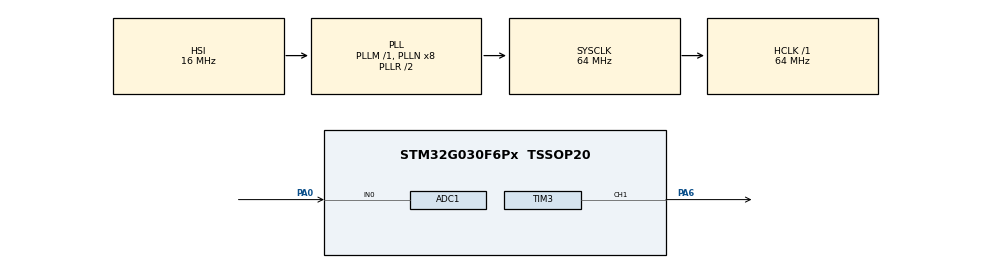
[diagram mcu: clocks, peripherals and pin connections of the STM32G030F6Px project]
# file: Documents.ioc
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ADC1.Channel-0\#ChannelRegularConversion=ADC_CHANNEL_0
ADC1.NbrOfConversionFlag=1
ADC1.Rank-0\#ChannelRegularConversion=1
ADC1.SamplingTime-0\#ChannelRegularConversion=ADC_SAMPLINGTIME_COMMON_1
ADC1.SamplingTimeCommon1=ADC_SAMPLETIME_160CYCLES_5
ADC1.SelectedChannel=ADC_CHANNEL_0
ADC1.master=1
Dma.Request0=TIM3_CH1
Dma.TIM3_CH1.0.Direction=DMA_MEMORY_TO_PERIPH
Dma.TIM3_CH1.0.EventEnable=DISABLE
Dma.TIM3_CH1.0.Instance=DMA1_Channel1
Dma.TIM3_CH1.0.MemDataAlignment=DMA_MDATAALIGN_HALFWORD
Dma.TIM3_CH1.0.MemInc=DMA_MINC_ENABLE
Dma.TIM3_CH1.0.Mode=DMA_NORMAL
Dma.TIM3_CH1.0.PeriphDataAlignment=DMA_PDATAALIGN_HALFWORD
Dma.TIM3_CH1.0.PeriphInc=DMA_PINC_DISABLE
Dma.TIM3_CH1.0.Polarity=HAL_DMAMUX_REQ_GEN_RISING
Dma.TIM3_CH1.0.Priority=DMA_PRIORITY_LOW
Dma.TIM3_CH1.0.RequestNumber=1
Dma.TIM3_CH1.0.SignalID=NONE
Dma.TIM3_CH1.0.SyncEnable=DISABLE
Dma.TIM3_CH1.0.SyncPolarity=HAL_DMAMUX_SYNC_NO_EVENT
Dma.TIM3_CH1.0.SyncRequestNumber=1
Dma.TIM3_CH1.0.SyncSignalID=NONE
Mcu.Family=STM32G0
Mcu.Name=STM32G030F6Px
Mcu.Package=TSSOP20
NVIC.DMA1_Channel1_IRQn=true\:0\:0\:false\:false\:true\:false\:true\:true
PA0.Mode=IN0
PA0.Signal=ADC1_IN0
PA13.Mode=Serial_Wire
PA13.Signal=SYS_SWDIO
PA14-BOOT0.Mode=Serial_Wire
PA14-BOOT0.Signal=SYS_SWCLK
PA14-BOOT0__PA15.StandardMode=true
PA6.Signal=S_TIM3_CH1
PB0__PB1__PB2__PA8.StandardMode=true
PB3__PB4__PB5__PB6.StandardMode=true
PB7__PB8.StandardMode=true
PC14-OSC32_IN\ (PC14)__PB9.StandardMode=true
ProjectManager.HeapSize=0x200
ProjectManager.StackSize=0x400
ProjectManager.TargetToolchain=Makefile
RCC.ADCFreq_Value=64000000
RCC.AHBFreq_Value=64000000
RCC.CortexFreq_Value=64000000
RCC.EXTERNAL_CLOCK_VALUE=12288000
RCC.HCLKFreq_Value=64000000
RCC.HSE_VALUE=8000000
RCC.HSI_VALUE=16000000
RCC.LSE_VALUE=32768
RCC.SYSCLKFreq_VALUE=64000000
RCC.SYSCLKSource=RCC_SYSCLKSOURCE_PLLCLK
RCC.VCOOutputFreq_Value=128000000
SH.S_TIM3_CH1.0=TIM3_CH1,PWM Generation1 CH1
TIM3.AutoReloadPreload=TIM_AUTORELOAD_PRELOAD_ENABLE
TIM3.Channel-PWM\ Generation1\ CH1=TIM_CHANNEL_1
TIM3.CounterMode=TIM_COUNTERMODE_UP
TIM3.Period=79
VP_TIM3_VS_ClockSourceINT.Mode=Internal
board=custom

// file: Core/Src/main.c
/* USER CODE BEGIN Header */
/**
  ******************************************************************************
  * @file           : main.c
  * @brief          : Main program body
  ******************************************************************************
  * @attention
  *
  * Copyright (c) 2026 STMicroelectronics.
  * All rights reserved.
  *
  * This software is licensed under terms that can be found in the LICENSE file
  * in the root directory of this software component.
  * If no LICENSE file comes with this software, it is provided AS-IS.
  *
  ******************************************************************************
  */
/* USER CODE END Header */
#include "main.h"

/* USER CODE BEGIN Includes */
#include "ws2812.h"
/* USER CODE END Includes */

/* USER CODE BEGIN PTD */
typedef struct{
    uint8_t r;
    uint8_t g;
    uint8_t b;
} rgb_t;
/* USER CODE END PTD */

/* USER CODE BEGIN PD */
#define DARK_TH_HIGH 2400U
#define DARK_TH_LOW 1800U
#define FRAME_PERIOD_MS 20U
/* USER CODE END PD */

ADC_HandleTypeDef hadc1;

TIM_HandleTypeDef htim3;
DMA_HandleTypeDef hdma_tim3_ch1;

void SystemClock_Config(void);
static void MX_GPIO_Init(void);
static void MX_DMA_Init(void);
static void MX_TIM3_Init(void);
static void MX_ADC1_Init(void);

/* USER CODE BEGIN 0 */
static uint16_t adc_read_raw(void) {
    uint16_t val = 0;
    HAL_ADC_Start(&hadc1);
    if (HAL_ADC_PollForConversion(&hadc1, 10) == HAL_OK) {
        val = (uint16_t)HAL_ADC_GetValue(&hadc1);
    }
    HAL_ADC_Stop(&hadc1);
    return val;
}
static uint8_t scale8(uint8_t val, uint8_t scale) {
    return (uint8_t)(((uint16_t)val * scale) >> 8);
}
static rgb_t color_wheel(uint8_t h){
  rgb_t c;
  if (h < 85U){
    c.r = 255U - h * 3U;
    c.g =  h * 3U;
    c.b = 0;
  }
  else if (h < 170U){
    h -= 85U;
    c.r = 0;
    c.g = 255U - h * 3U;
    c.b = h * 3U;
  }
  else{
    h -= 170U;
    c.r = h * 3U;
    c.g = 0;
    c.b = 255U - h * 3U;
  }
  return c;
}

/* USER CODE END 0 */

int main(void)
{

  /* MCU Configuration--------------------------------------------------------*/

  /* Reset of all peripherals, Initializes the Flash interface and the Systick. */
  HAL_Init();

  /* Configure the system clock */
  SystemClock_Config();

  /* Initialize all configured peripherals */
  MX_GPIO_Init();
  MX_DMA_Init();
  MX_TIM3_Init();
  MX_ADC1_Init();
  /* USER CODE BEGIN 2 */
  HAL_ADCEx_Calibration_Start(&hadc1);
  ws2812_init(&htim3);
  uint16_t adc_filtered = adc_read_raw();
  uint8_t is_dark = (adc_filtered > DARK_TH_HIGH) ? 1U : 0U;
  uint8_t cur_bright = is_dark ? 55U : 200U;
  uint32_t last_frame_ms = HAL_GetTick();
  int16_t breath = 45;
  int8_t breath_dir = 1;
  uint8_t hue = 0;
  /* USER CODE END 2 */

  /* Infinite loop */
  while (1)
  {

    /* USER CODE BEGIN 3 */
    uint32_t now = HAL_GetTick();
    if ((now - last_frame_ms) >= FRAME_PERIOD_MS) {
      last_frame_ms = now;

      uint16_t raw = adc_read_raw();
      adc_filtered = (uint16_t)(((uint32_t)adc_filtered * 7U + raw + 4U) >> 3);

      if (adc_filtered > DARK_TH_HIGH) {
        is_dark = 1U;
      } else if (adc_filtered < DARK_TH_LOW) {
        is_dark = 0U;
      }

      uint8_t target_bright = is_dark ? 55U : 200U;
      if (cur_bright + 2U < target_bright) {
        cur_bright += 2U;
      } else if (cur_bright > target_bright + 2U) {
        cur_bright -= 2U;
      } else {
        cur_bright = target_bright;
      }

      uint8_t breath_step = is_dark ? 2U : 5U;
      uint8_t hue_step = is_dark ? 1U : 3U;

      breath += (int16_t)breath_dir * (int16_t)breath_step;
      if (breath >= 255) {
        breath = 255;
        breath_dir = -1;
      } else if (breath <= 45) {
        breath = 45;
        breath_dir = 1;
      }

      hue += hue_step;

      uint8_t gamma = scale8((uint8_t)breath, (uint8_t)breath);
      uint8_t level = scale8(gamma, cur_bright);

      if (!ws2812_is_busy()) {
        for (uint8_t i = 0; i < WS2812_LED_COUNT; i++) {
          rgb_t c = color_wheel((uint8_t)(hue + i * 48U));
          ws2812_set_pixel(i, scale8(c.r, level), scale8(c.g, level), scale8(c.b, level));
        }
        ws2812_show();
      }
    }
  }
  /* USER CODE END 3 */
}

void SystemClock_Config(void)
{
  RCC_OscInitTypeDef RCC_OscInitStruct = {0};
  RCC_ClkInitTypeDef RCC_ClkInitStruct = {0};

  /** Configure the main internal regulator output voltage
  */
  HAL_PWREx_ControlVoltageScaling(PWR_REGULATOR_VOLTAGE_SCALE1);

  /** Initializes the RCC Oscillators according to the specified parameters
  * in the RCC_OscInitTypeDef structure.
  */
  RCC_OscInitStruct.OscillatorType = RCC_OSCILLATORTYPE_HSI;
  RCC_OscInitStruct.HSIState = RCC_HSI_ON;
  RCC_OscInitStruct.HSIDiv = RCC_HSI_DIV1;
  RCC_OscInitStruct.HSICalibrationValue = RCC_HSICALIBRATION_DEFAULT;
  RCC_OscInitStruct.PLL.PLLState = RCC_PLL_ON;
  RCC_OscInitStruct.PLL.PLLSource = RCC_PLLSOURCE_HSI;
  RCC_OscInitStruct.PLL.PLLM = RCC_PLLM_DIV1;
  RCC_OscInitStruct.PLL.PLLN = 8;
  RCC_OscInitStruct.PLL.PLLP = RCC_PLLP_DIV2;
  RCC_OscInitStruct.PLL.PLLR = RCC_PLLR_DIV2;
  if (HAL_RCC_OscConfig(&RCC_OscInitStruct) != HAL_OK)
  {
    Error_Handler();
  }

  /** Initializes the CPU, AHB and APB buses clocks
  */
  RCC_ClkInitStruct.ClockType = RCC_CLOCKTYPE_HCLK|RCC_CLOCKTYPE_SYSCLK
                              |RCC_CLOCKTYPE_PCLK1;
  RCC_ClkInitStruct.SYSCLKSource = RCC_SYSCLKSOURCE_PLLCLK;
  RCC_ClkInitStruct.AHBCLKDivider = RCC_SYSCLK_DIV1;
  RCC_ClkInitStruct.APB1CLKDivider = RCC_HCLK_DIV1;

  if (HAL_RCC_ClockConfig(&RCC_ClkInitStruct, FLASH_LATENCY_2) != HAL_OK)
  {
    Error_Handler();
  }
}

static void MX_ADC1_Init(void)
{

  ADC_ChannelConfTypeDef sConfig = {0};

  /** Configure the global features of the ADC (Clock, Resolution, Data Alignment and number of conversion)
  */
  hadc1.Instance = ADC1;
  hadc1.Init.ClockPrescaler = ADC_CLOCK_SYNC_PCLK_DIV2;
  hadc1.Init.Resolution = ADC_RESOLUTION_12B;
  hadc1.Init.DataAlign = ADC_DATAALIGN_RIGHT;
  hadc1.Init.ScanConvMode = ADC_SCAN_DISABLE;
  hadc1.Init.EOCSelection = ADC_EOC_SINGLE_CONV;
  hadc1.Init.LowPowerAutoWait = DISABLE;
  hadc1.Init.LowPowerAutoPowerOff = DISABLE;
  hadc1.Init.ContinuousConvMode = DISABLE;
  hadc1.Init.NbrOfConversion = 1;
  hadc1.Init.DiscontinuousConvMode = DISABLE;
  hadc1.Init.ExternalTrigConv = ADC_SOFTWARE_START;
  hadc1.Init.ExternalTrigConvEdge = ADC_EXTERNALTRIGCONVEDGE_NONE;
  hadc1.Init.DMAContinuousRequests = DISABLE;
  hadc1.Init.Overrun = ADC_OVR_DATA_PRESERVED;
  hadc1.Init.SamplingTimeCommon1 = ADC_SAMPLETIME_160CYCLES_5;
  hadc1.Init.SamplingTimeCommon2 = ADC_SAMPLETIME_1CYCLE_5;
  hadc1.Init.OversamplingMode = DISABLE;
  hadc1.Init.TriggerFrequencyMode = ADC_TRIGGER_FREQ_HIGH;
  if (HAL_ADC_Init(&hadc1) != HAL_OK)
  {
    Error_Handler();
  }

  /** Configure Regular Channel
  */
  sConfig.Channel = ADC_CHANNEL_0;
  sConfig.Rank = ADC_REGULAR_RANK_1;
  sConfig.SamplingTime = ADC_SAMPLINGTIME_COMMON_1;
  if (HAL_ADC_ConfigChannel(&hadc1, &sConfig) != HAL_OK)
  {
    Error_Handler();
  }

}

static void MX_TIM3_Init(void)
{

  TIM_ClockConfigTypeDef sClockSourceConfig = {0};
  TIM_MasterConfigTypeDef sMasterConfig = {0};
  TIM_OC_InitTypeDef sConfigOC = {0};

  htim3.Instance = TIM3;
  htim3.Init.Prescaler = 0;
  htim3.Init.CounterMode = TIM_COUNTERMODE_UP;
  htim3.Init.Period = 79;
  htim3.Init.ClockDivision = TIM_CLOCKDIVISION_DIV1;
  htim3.Init.AutoReloadPreload = TIM_AUTORELOAD_PRELOAD_ENABLE;
  if (HAL_TIM_Base_Init(&htim3) != HAL_OK)
  {
    Error_Handler();
  }
  sClockSourceConfig.ClockSource = TIM_CLOCKSOURCE_INTERNAL;
  if (HAL_TIM_ConfigClockSource(&htim3, &sClockSourceConfig) != HAL_OK)
  {
    Error_Handler();
  }
  if (HAL_TIM_PWM_Init(&htim3) != HAL_OK)
  {
    Error_Handler();
  }
  sMasterConfig.MasterOutputTrigger = TIM_TRGO_RESET;
  sMasterConfig.MasterSlaveMode = TIM_MASTERSLAVEMODE_DISABLE;
  if (HAL_TIMEx_MasterConfigSynchronization(&htim3, &sMasterConfig) != HAL_OK)
  {
    Error_Handler();
  }
  sConfigOC.OCMode = TIM_OCMODE_PWM1;
  sConfigOC.Pulse = 0;
  sConfigOC.OCPolarity = TIM_OCPOLARITY_HIGH;
  sConfigOC.OCFastMode = TIM_OCFAST_DISABLE;
  if (HAL_TIM_PWM_ConfigChannel(&htim3, &sConfigOC, TIM_CHANNEL_1) != HAL_OK)
  {
    Error_Handler();
  }
  HAL_TIM_MspPostInit(&htim3);

}

static void MX_DMA_Init(void)
{

  /* DMA controller clock enable */
  __HAL_RCC_DMA1_CLK_ENABLE();

  /* DMA interrupt init */
  /* DMA1_Channel1_IRQn interrupt configuration */
  HAL_NVIC_SetPriority(DMA1_Channel1_IRQn, 0, 0);
  HAL_NVIC_EnableIRQ(DMA1_Channel1_IRQn);

}

static void MX_GPIO_Init(void)
{

  /* GPIO Ports Clock Enable */
  __HAL_RCC_GPIOA_CLK_ENABLE();

}

void Error_Handler(void)
{
  __disable_irq();
  while (1)
  {
  }
}
